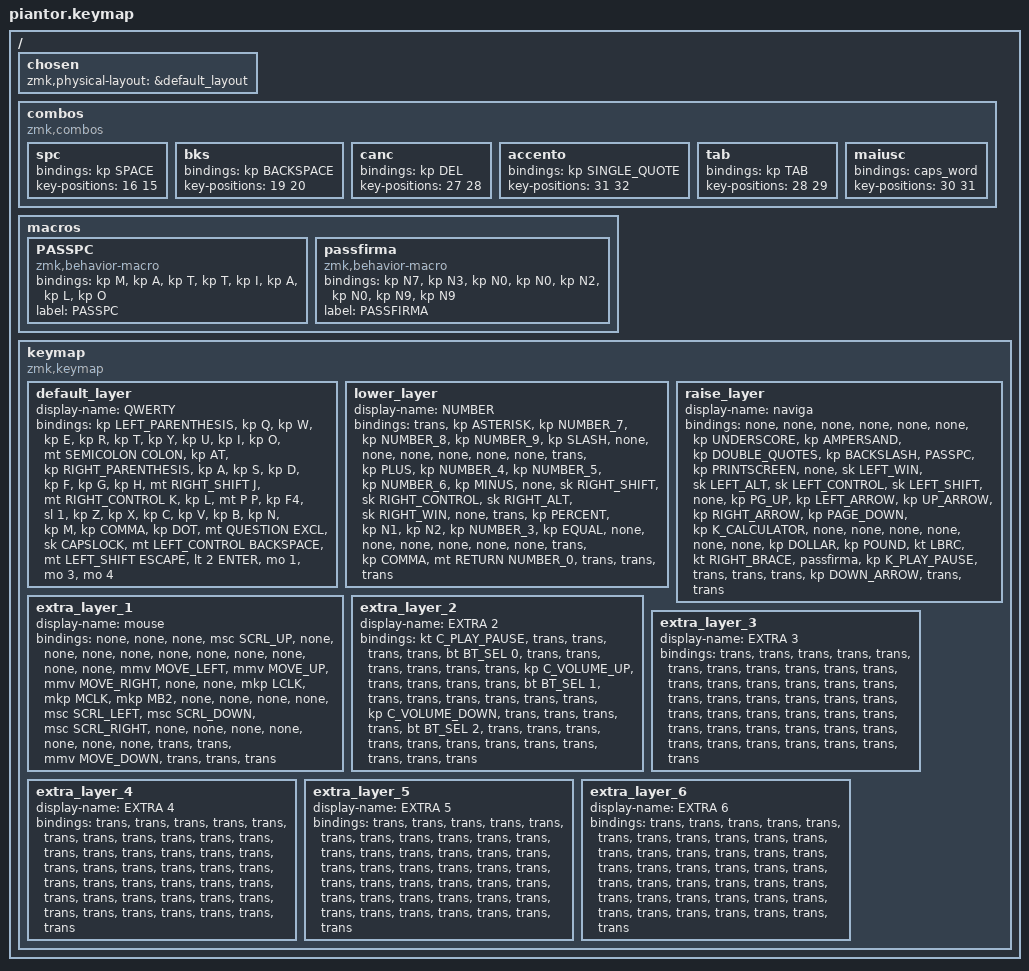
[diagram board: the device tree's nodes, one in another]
/*
    No chosen zmk,matrix-transform here if using ZMK stuidio.
    https://zmk.dev/docs/features/studio#adding-zmk-studio-support-to-a-keyboard

    Put trackball listener here and place input-processors inside!
*/

#include <input/processors.dtsi>
#include <dt-bindings/zmk/mouse.h>
#include <dt-bindings/zmk/input_transform.h>
#include <zephyr/dt-bindings/input/input-event-codes.h>
#include <behaviors.dtsi>
#include <dt-bindings/zmk/bt.h>
#include <dt-bindings/zmk/keys.h>
#include <dt-bindings/zmk/pointing.h>

#define ZMK_POINTING_DEFAULT_MOVE_VAL 1500  // default: 600
#define ZMK_POINTING_DEFAULT_SCRL_VAL 20    // default: 10

/ {
    chosen { zmk,physical-layout = &default_layout; };
};

/ {
    combos {
        compatible = "zmk,combos";

        spc {
            bindings = <&kp SPACE>;
            key-positions = <16 15>;
        };

        bks {
            bindings = <&kp BACKSPACE>;
            key-positions = <19 20>;
        };

        canc {
            bindings = <&kp DEL>;
            key-positions = <27 28>;
        };

        accento {
            bindings = <&kp SINGLE_QUOTE>;
            key-positions = <31 32>;
        };

        tab {
            bindings = <&kp TAB>;
            key-positions = <28 29>;
        };

        maiusc {
            bindings = <&caps_word>;
            key-positions = <30 31>;
        };
    };

    macros {
        PASSPC: PASSPC {
            compatible = "zmk,behavior-macro";
            #binding-cells = <0>;
            bindings = <&kp M &kp A &kp T &kp T &kp I &kp A &kp L &kp O>;
            label = "PASSPC";
        };

        passfirma: passfirma {
            compatible = "zmk,behavior-macro";
            #binding-cells = <0>;
            bindings = <&kp N7 &kp N3 &kp N0 &kp N0 &kp N2 &kp N0 &kp N9 &kp N9>;
            label = "PASSFIRMA";
        };
    };

    keymap {
        compatible = "zmk,keymap";

        default_layer {
            display-name = "QWERTY";

            // --------------------------------------------------------------------------------
            // |  TAB |  Q  |  W  |  E  |  R  |  T  |  Y  |  U   |  I  |  O  |  P  | BSPC |
            // | CTRL |  A  |  S  |  D  |  F  |  G  |  H  |  J   |  K  |  L  |  ;  |  '   |
            // | SHFT |  Z  |  X  |  C  |  V  |  B  |  N  |  M   |  ,  |  .  |  /  | ESC  |
            //                    | GUI | LWR | SPC | ENT | RSE  | ALT |

            bindings = <
&kp LEFT_PARENTHESIS  &kp Q  &kp W  &kp E  &kp R  &kp T  &kp Y  &kp U  &kp I  &kp O  &mt SEMICOLON COLON  &kp AT  &kp RIGHT_PARENTHESIS  &kp A  &kp S  &kp D  &kp F  &kp G  &kp H  &mt RIGHT_SHIFT J  &mt RIGHT_CONTROL K  &kp L  &mt P P  &kp F4  &sl 1  &kp Z  &kp X  &kp C  &kp V  &kp B  &kp N  &kp M  &kp COMMA  &kp DOT  &mt QUESTION EXCL  &sk CAPSLOCK  &mt LEFT_CONTROL BACKSPACE  &mt LEFT_SHIFT ESCAPE  &lt 2 ENTER  &mo 1  &mo 3  &mo 4
            >;
        };

        lower_layer {
            display-name = "NUMBER";

            // -----------------------------------------------------------------------------------------
            // |  TAB |  1  |  2  |  3  |  4  |  5    |  6  |  7  |  8  |  9  |  0  | BSPC |
            // | CTRL | BT1 | BT2 | BT3 | BT4 | BT5   | LFT | DWN |  UP | RGT |     |      |
            // | SHFT | BTCR| RGB | RST | BOOT| Unlock|     |     |     |     |     |      |
            //                    | GUI |     | SPC   | ENT |     | ALT |

            bindings = <
&trans  &kp ASTERISK  &kp NUMBER_7  &kp NUMBER_8  &kp NUMBER_9  &kp SLASH  &none  &none  &none  &none  &none  &none  &trans  &kp PLUS  &kp NUMBER_4  &kp NUMBER_5  &kp NUMBER_6  &kp MINUS  &none  &sk RIGHT_SHIFT  &sk RIGHT_CONTROL  &sk RIGHT_ALT  &sk RIGHT_WIN  &none  &trans  &kp PERCENT  &kp N1  &kp N2  &kp NUMBER_3  &kp EQUAL  &none  &none  &none  &none  &none  &none  &trans  &kp COMMA  &mt RETURN NUMBER_0  &trans  &trans  &trans
            >;
        };

        raise_layer {
            display-name = "naviga";

            // -----------------------------------------------------------------------------------------
            // |  TAB |  !  |  @  |  #  |  $  |  %  |  ^  |  &  |  *  |  (  |  )  | BSPC |
            // | CTRL |     |     |     |     |     |  -  |  =  |  [  |  ]  |  \  |  `   |
            // | SHFT |     |     |     |     |     |  _  |  +  |  {  |  }  | "|" |  ~   |
            //                    | GUI |     | SPC | ENT |     | ALT |

            bindings = <
&none  &none  &none  &none  &none  &none  &kp UNDERSCORE  &kp AMPERSAND  &kp DOUBLE_QUOTES  &kp BACKSLASH  &PASSPC  &kp PRINTSCREEN  &none  &sk LEFT_WIN  &sk LEFT_ALT  &sk LEFT_CONTROL  &sk LEFT_SHIFT  &none  &kp PG_UP  &kp LEFT_ARROW  &kp UP_ARROW  &kp RIGHT_ARROW  &kp PAGE_DOWN  &kp K_CALCULATOR  &none  &none  &none  &none  &none  &none  &kp DOLLAR  &kp POUND  &kt LBRC  &kt RIGHT_BRACE  &passfirma  &kp K_PLAY_PAUSE  &trans  &trans  &trans  &kp DOWN_ARROW  &trans  &trans
            >;
        };

        extra_layer_1 {
            display-name = "mouse";
            bindings = <
&none  &none  &none  &msc SCRL_UP  &none  &none  &none  &none  &none  &none  &none  &none  &none  &none  &mmv MOVE_LEFT  &mmv MOVE_UP  &mmv MOVE_RIGHT  &none  &none  &mkp LCLK  &mkp MCLK  &mkp MB2  &none  &none  &none  &none  &msc SCRL_LEFT  &msc SCRL_DOWN  &msc SCRL_RIGHT  &none  &none  &none  &none  &none  &none  &none  &trans  &trans  &mmv MOVE_DOWN  &trans  &trans  &trans
            >;
        };

        extra_layer_2 {
            display-name = "EXTRA 2";
            bindings = <
&kt C_PLAY_PAUSE  &trans  &trans  &trans  &trans  &bt BT_SEL 0  &trans  &trans  &trans  &trans  &trans  &trans  &kp C_VOLUME_UP  &trans  &trans  &trans  &trans  &bt BT_SEL 1  &trans  &trans  &trans  &trans  &trans  &trans  &kp C_VOLUME_DOWN  &trans  &trans  &trans  &trans  &bt BT_SEL 2  &trans  &trans  &trans  &trans  &trans  &trans  &trans  &trans  &trans  &trans  &trans  &trans
            >;
        };

        extra_layer_3 {
            display-name = "EXTRA 3";
            bindings = <
&trans  &trans  &trans  &trans  &trans  &trans  &trans  &trans  &trans  &trans  &trans  &trans  &trans  &trans  &trans  &trans  &trans  &trans  &trans  &trans  &trans  &trans  &trans  &trans  &trans  &trans  &trans  &trans  &trans  &trans  &trans  &trans  &trans  &trans  &trans  &trans  &trans  &trans  &trans  &trans  &trans  &trans
            >;
        };

        extra_layer_4 {
            display-name = "EXTRA 4";
            bindings = <
&trans  &trans  &trans  &trans  &trans  &trans  &trans  &trans  &trans  &trans  &trans  &trans  &trans  &trans  &trans  &trans  &trans  &trans  &trans  &trans  &trans  &trans  &trans  &trans  &trans  &trans  &trans  &trans  &trans  &trans  &trans  &trans  &trans  &trans  &trans  &trans  &trans  &trans  &trans  &trans  &trans  &trans
            >;
        };

        extra_layer_5 {
            display-name = "EXTRA 5";
            bindings = <
&trans  &trans  &trans  &trans  &trans  &trans  &trans  &trans  &trans  &trans  &trans  &trans  &trans  &trans  &trans  &trans  &trans  &trans  &trans  &trans  &trans  &trans  &trans  &trans  &trans  &trans  &trans  &trans  &trans  &trans  &trans  &trans  &trans  &trans  &trans  &trans  &trans  &trans  &trans  &trans  &trans  &trans
            >;
        };

        extra_layer_6 {
            display-name = "EXTRA 6";
            bindings = <
&trans  &trans  &trans  &trans  &trans  &trans  &trans  &trans  &trans  &trans  &trans  &trans  &trans  &trans  &trans  &trans  &trans  &trans  &trans  &trans  &trans  &trans  &trans  &trans  &trans  &trans  &trans  &trans  &trans  &trans  &trans  &trans  &trans  &trans  &trans  &trans  &trans  &trans  &trans  &trans  &trans  &trans
            >;
        };
    };
};
